# CYBLE_416045_02 register map
File version: 0.1
PSoC 63
Registers are 32-bit, read-write, no defined reset value unless marked. A register's access mark holds for its fields unless they carry their own. Offsets are from the block's base; lines under a group give offsets from that group; [hi:lo] are bit positions; {n}, {i} and the like mark numbered series; 'fields as' and 'values as' point back to an identical list; <NAME> marks a mode.

## Memory map
0x00000000 OP0
0x00000000 OP1
0x00000000 ANALYZER_VDAC

## ANALYZER_VDAC
Base 0x00000000
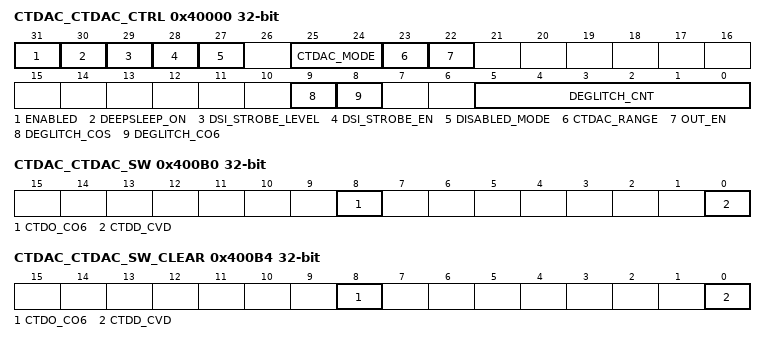
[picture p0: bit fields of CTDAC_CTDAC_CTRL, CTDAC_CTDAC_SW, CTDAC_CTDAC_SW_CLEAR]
0x40000 CTDAC_CTDAC_CTRL — Global CTDAC control
  [31] ENABLED — 0: CTDAC IP disabled (put analog in power down, open all switches)?1: CTDAC IP enabled
  [30] DEEPSLEEP_ON — - 0: CTDAC IP disabled off during DeepSleep power mode?- 1: CTDAC IP remains enabled during DeepSleep power mode (if ENABLED=1)
  [29] DSI_STROBE_LEVEL — Select level or edge detect for DSI strobe?- 0: DSI strobe signal is a pulse input, after a positive edge is detected on the DSI strobe signal the next DAC value update is done on the next CTDAC clock?- 1: DSI strobe signal is a level input, as long as the DSI strobe signal remains high the CTDAC will do a next DAC value update on each CTDAC clock.
  [28] DSI_STROBE_EN — DSI strobe input Enable. This enables CTDAC updates to be further throttled by DSI.?0: Ignore DSI strobe input?1: Only do a CTDAC update if alllowed by the DSI stobe (throttle), see below for level or edge
  [27] DISABLED_MODE — Select the output value when the output is disabled (OUT_EN=0) (for risk mitigation)?0: Tri-state CTDAC output when disabled?1: output Vssa or Vref when disabled (see OUT_EN description)
  [25:24] CTDAC_MODE — DAC mode, this determines the Value decoding
    0=UNSIGNED12 (Unsigned 12-bit VDAC, i.e. no value decoding.); 1=VIRT_SIGNED12 (Virtual signed 12-bits' VDAC. Value decoding: ?add 0x800 to the 12-bit Value (=invert MSB), to convert the lowest signed number 0x800 to the lowest unsigned number 0x000. This is the same as the SAR handles 12-bit 'virtual' signed numbers.)
  [23] CTDAC_RANGE — By closing the bottom switch in the R2R network the output is lifted by one LSB, effectively adding 1?0: Range is [0, 4095] * Vref / 4096 ?1: Range is [1, 4096] * Vref / 4096
  [22] OUT_EN — Output enable, intended to be used during the Hold phase of the Sample and Hold when power cycling :?0: output disabled, the output is either: ? - Tri-state (DISABLED_MODE=0) ? - or Vssa (DISABLED_MODE=1 && CTDAC_RANGE=0) ? - or Vref (DISABLED_MODE=1 && CTDAC_RANGE=1) ?1: output enabled, CTDAC output drives the programmed VALUE
  [9] DEGLITCH_COS — Force CTB.COS switch open after each VALUE change for the set number of clock cycles.
  [8] DEGLITCH_CO6 — Force CTDAC.CO6 switch open after each VALUE change for the set number of clock cycles.
  [5:0] DEGLITCH_CNT — To prevent glitches after VALUE changes from propagating, the output switch can be opened for DEGLITCH_CNT+1 clk_ctdac clock cycles.
0x40020 CTDAC_INTR — Interrupt request register
  [0] VDAC_EMPTY — VDAC Interrupt: hardware sets this interrupt when VDAC next value field is empty, i.e. was copied to the current VALUE. Write with '1' to clear bit.
0x40024 CTDAC_INTR_SET — Interrupt request set register
  [0] VDAC_EMPTY_SET — Write with '1' to set corresponding bit in interrupt request register.
0x40028 CTDAC_INTR_MASK — Interrupt request mask
  [0] VDAC_EMPTY_MASK — Mask bit for corresponding bit in interrupt request register.
0x4002C CTDAC_INTR_MASKED — Interrupt request masked
  [0] VDAC_EMPTY_MASKED ro — Logical and of corresponding request and mask bits.
0x400B0 CTDAC_CTDAC_SW — CTDAC switch control
  [8] CTDO_CO6 — ctdvout to P6 pin. Note this switch will temporarily be opened for deglitching if DEGLITCH_CO6 is set
  [0] CTDD_CVD — VDDA supply to ctdrefdrive
0x400B4 CTDAC_CTDAC_SW_CLEAR — CTDAC switch control clear
  [8] CTDO_CO6 — see corresponding bit in CTD_SW
  [0] CTDD_CVD — see corresponding bit in CTD_SW
0x40100 CTDAC_CTDAC_VAL — DAC Value
  [11:0] VALUE — Value, in CTDAC_MODE 1 this value is decoded
0x40104 CTDAC_CTDAC_VAL_NXT — Next DAC value (double buffering)
  [11:0] VALUE — Next value for CTDAC_VAL.VALUE
